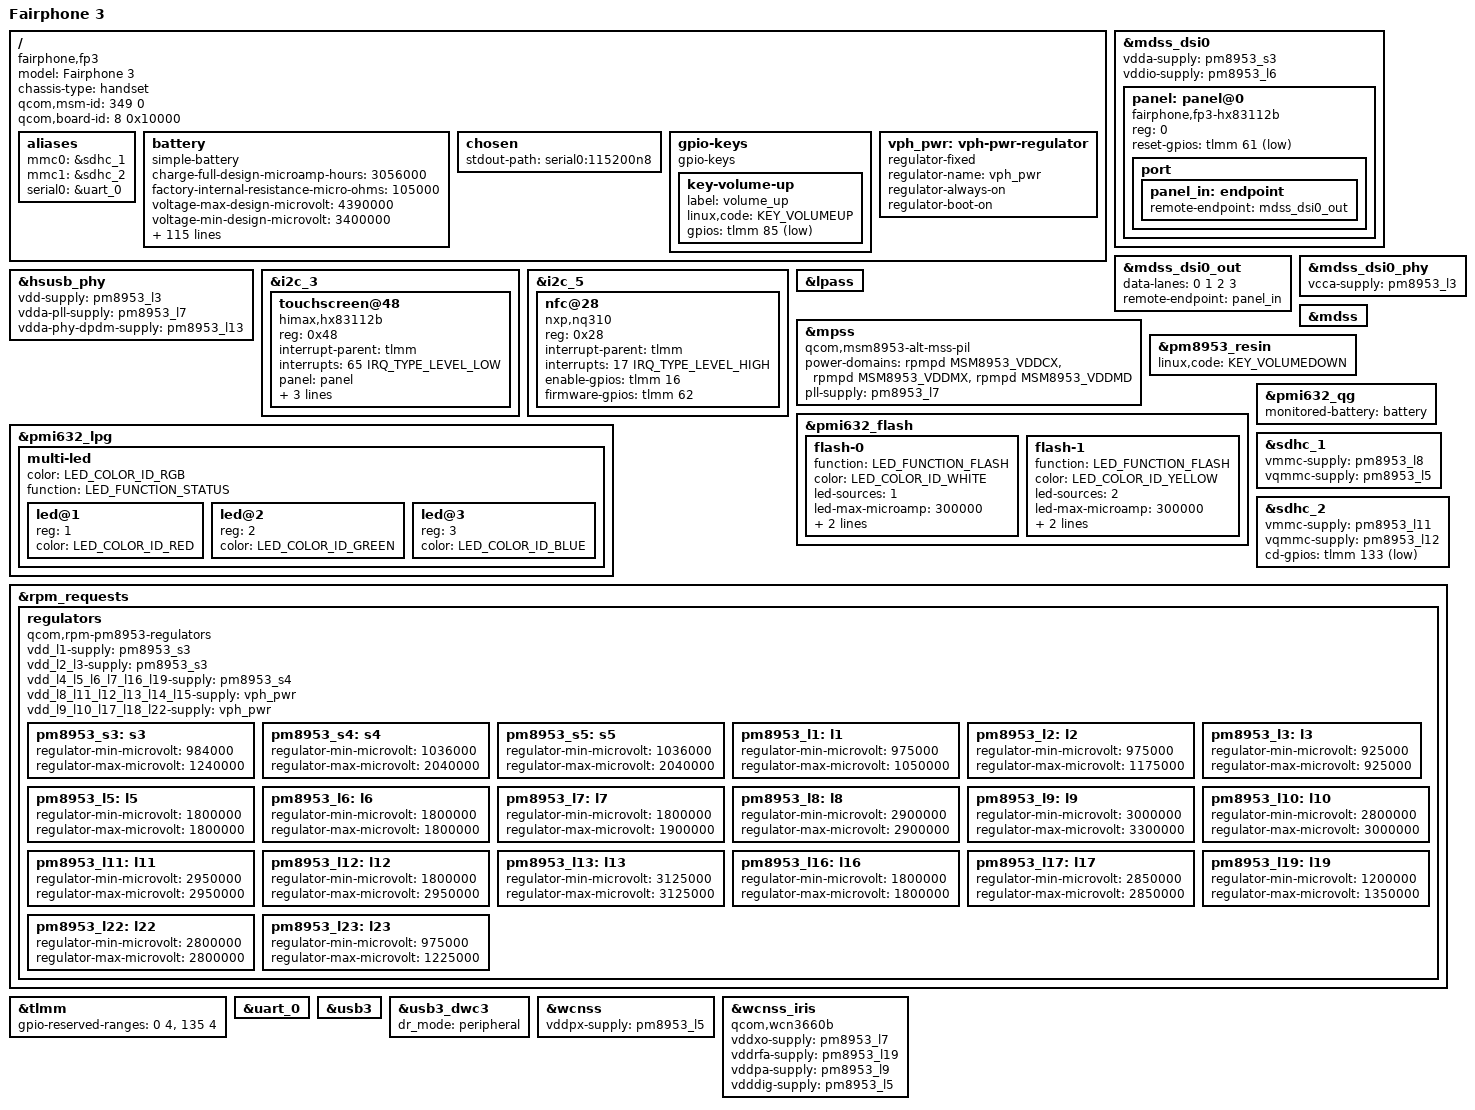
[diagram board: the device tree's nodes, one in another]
// SPDX-License-Identifier: BSD-3-Clause
/*
 * Copyright (c) 2022, Luca Weiss <luca@z3ntu.xyz>
 */
/dts-v1/;

#include <dt-bindings/leds/common.h>
#include "sdm632.dtsi"
#include "pm8953.dtsi"
#include "pmi632.dtsi"

/ {
	model = "Fairphone 3";
	compatible = "fairphone,fp3", "qcom,sdm632";
	chassis-type = "handset";
	qcom,msm-id = <349 0>;
	qcom,board-id = <8 0x10000>;

	aliases {
		mmc0 = &sdhc_1;
		mmc1 = &sdhc_2;
		serial0 = &uart_0;
	};

	battery: battery {
		compatible = "simple-battery";

		charge-full-design-microamp-hours = <3056000>; // capacity a 25 celsius when charging
		// improved guess by using the esr measuring method from qpnp-qg.c
		// which seems to tediuos to use every time
		factory-internal-resistance-micro-ohms = <105000>;
		voltage-max-design-microvolt = <4390000>;      // from downstream devicetree
		voltage-min-design-microvolt = <3400000>;      // from DEFAULT_VBATT_CUTOFF_MV in qpnp-qg.c

		// This is the lookup table for the non-charging case.
		// To have lookup tables for the charging case, too, we could
		// add them here with higher temperatur (T + 200) and request
		// the capacity for (T + 200) if we are charging
		ocv-capacity-celsius = <(-10) 0 10 25 40 50>; // 200 210 225 240 250>;
		ocv-capacity-table-0 = <4391500 100>, <4353500 98>, <4319200 96>, <4289300 94>, <4263100 92>,
				       <4238100 90>, <4213700 88>, <4189800 86>, <4163800 84>, <4136000 82>,
				       <4114900 80>, <4102900 78>, <4090800 76>, <4065400 74>, <4024600 72>,
				       <3990900 70>, <3966300 68>, <3945700 66>, <3928700 64>, <3914100 62>,
				       <3898800 60>, <3882100 58>, <3866000 56>, <3851200 54>, <3837500 52>,
				       <3827000 50>, <3818800 48>, <3811800 46>, <3805500 44>, <3799900 42>,
				       <3794700 40>, <3789900 38>, <3785300 36>, <3780500 34>, <3775700 32>,
				       <3770500 30>, <3765100 28>, <3759000 26>, <3751800 24>, <3743900 22>,
				       <3735900 20>, <3727400 18>, <3719500 16>, <3711700 14>, <3703500 12>,
				       <3694800 10>, <3689800 9>, <3684300 8>, <3676400 7>, <3663200 6>,
				       <3640100 5>, <3603400 4>, <3547700 3>, <3466700 2>, <3335700 1>,
				       <2958400 0>;
		ocv-capacity-table-1 = <4387000 100>, <4350300 98>, <4317100 96>, <4288000 94>, <4262400 92>,
				       <4237700 90>, <4212800 88>, <4188600 86>, <4165200 84>, <4142300 82>,
				       <4121800 80>, <4105500 78>, <4089100 76>, <4066200 74>, <4037000 72>,
				       <4009500 70>, <3984500 68>, <3961500 66>, <3942200 64>, <3924900 62>,
				       <3907700 60>, <3890000 58>, <3873400 56>, <3858800 54>, <3845600 52>,
				       <3833200 50>, <3821000 48>, <3811000 46>, <3803900 44>, <3798200 42>,
				       <3793500 40>, <3789700 38>, <3786100 36>, <3782700 34>, <3779300 32>,
				       <3775100 30>, <3770200 28>, <3764700 26>, <3758300 24>, <3750900 22>,
				       <3742100 20>, <3731600 18>, <3719700 16>, <3707100 14>, <3696100 12>,
				       <3686700 10>, <3681900 9>, <3677200 8>, <3670100 7>, <3659500 6>,
				       <3639500 5>, <3601700 4>, <3543700 3>, <3460400 2>, <3326600 1>,
				       <2957900 0>;
		ocv-capacity-table-2 = <4385000 100>, <4352600 98>, <4322600 96>, <4295500 94>, <4271100 92>,
				       <4247300 90>, <4223500 88>, <4200200 86>, <4177400 84>, <4155000 82>,
				       <4133300 80>, <4112600 78>, <4092300 76>, <4072300 74>, <4052500 72>,
				       <4031100 70>, <4006600 68>, <3982900 66>, <3964500 64>, <3948600 62>,
				       <3930800 60>, <3909700 58>, <3889800 56>, <3873800 54>, <3859900 52>,
				       <3847400 50>, <3836300 48>, <3826300 46>, <3817400 44>, <3809300 42>,
				       <3801600 40>, <3794100 38>, <3787900 36>, <3783500 34>, <3779800 32>,
				       <3775900 30>, <3772000 28>, <3767600 26>, <3762200 24>, <3755800 22>,
				       <3747700 20>, <3737100 18>, <3724900 16>, <3710800 14>, <3696600 12>,
				       <3689000 10>, <3686700 9>, <3684100 8>, <3680500 7>, <3672600 6>,
				       <3651300 5>, <3606600 4>, <3542100 3>, <3456400 2>, <3327000 1>,
				       <2954300 0>;
		ocv-capacity-table-3 = <4382000 100>, <4351500 98>, <4323100 96>, <4296900 94>, <4272800 92>,
				       <4249100 90>, <4225600 88>, <4202300 86>, <4179500 84>, <4156900 82>,
				       <4134700 80>, <4112700 78>, <4091500 76>, <4072000 74>, <4053600 72>,
				       <4033700 70>, <4010700 68>, <3989500 66>, <3974200 64>, <3961400 62>,
				       <3944400 60>, <3920500 58>, <3897600 56>, <3879700 54>, <3864200 52>,
				       <3851300 50>, <3840500 48>, <3830800 46>, <3821700 44>, <3813400 42>,
				       <3806100 40>, <3799300 38>, <3793000 36>, <3786900 34>, <3781200 32>,
				       <3775500 30>, <3769800 28>, <3763600 26>, <3756500 24>, <3748800 22>,
				       <3741000 20>, <3732500 18>, <3721500 16>, <3707900 14>, <3693000 12>,
				       <3688100 10>, <3686700 9>, <3685300 8>, <3682300 7>, <3676300 6>,
				       <3655100 5>, <3610100 4>, <3550400 3>, <3470700 2>, <3353300 1>,
				       <2954000 0>;
		ocv-capacity-table-4 = <4377000 100>, <4348300 98>, <4321200 96>, <4295700 94>, <4271900 92>,
				       <4248400 90>, <4225000 88>, <4201800 86>, <4178900 84>, <4156300 82>,
				       <4134000 80>, <4112300 78>, <4091000 76>, <4070700 74>, <4050800 72>,
				       <4031600 70>, <4012500 68>, <3994300 66>, <3977800 64>, <3962200 62>,
				       <3944000 60>, <3921700 58>, <3900200 56>, <3882000 54>, <3865800 52>,
				       <3852600 50>, <3841800 48>, <3832100 46>, <3823200 44>, <3814900 42>,
				       <3807500 40>, <3800500 38>, <3794000 36>, <3788400 34>, <3782600 32>,
				       <3774900 30>, <3765200 28>, <3755900 26>, <3747400 24>, <3739200 22>,
				       <3731600 20>, <3723700 18>, <3712900 16>, <3699200 14>, <3685200 12>,
				       <3681600 10>, <3680800 9>, <3679300 8>, <3676500 7>, <3669600 6>,
				       <3643500 5>, <3597000 4>, <3535600 3>, <3452400 2>, <3329900 1>,
				       <2955200 0>;
		ocv-capacity-table-5 = <4375000 100>, <4347100 98>, <4320500 96>, <4295400 94>, <4271700 92>,
				       <4248300 90>, <4225000 88>, <4201800 86>, <4178900 84>, <4156400 82>,
				       <4134100 80>, <4112300 78>, <4090900 76>, <4070500 74>, <4050600 72>,
				       <4031500 70>, <4012800 68>, <3994900 66>, <3978300 64>, <3962300 62>,
				       <3943900 60>, <3921900 58>, <3900700 56>, <3882600 54>, <3866500 52>,
				       <3853200 50>, <3842300 48>, <3832500 46>, <3823400 44>, <3815000 42>,
				       <3807400 40>, <3800200 38>, <3793600 36>, <3788000 34>, <3782100 32>,
				       <3773300 30>, <3761000 28>, <3750000 26>, <3741100 24>, <3732800 22>,
				       <3725000 20>, <3717000 18>, <3706200 16>, <3692600 14>, <3679300 12>,
				       <3676300 10>, <3675200 9>, <3673600 8>, <3671000 7>, <3662500 6>,
				       <3633500 5>, <3586000 4>, <3524200 3>, <3439600 2>, <3314800 1>,
				       <2955300 0>;
	};

	chosen {
		stdout-path = "serial0:115200n8";
	};

	gpio-keys {
		compatible = "gpio-keys";

		key-volume-up {
			label = "volume_up";
			linux,code = <KEY_VOLUMEUP>;
			gpios = <&tlmm 85 GPIO_ACTIVE_LOW>;
		};
	};

	vph_pwr: vph-pwr-regulator {
		compatible = "regulator-fixed";
		regulator-name = "vph_pwr";
		regulator-always-on;
		regulator-boot-on;
	};
};

&mdss_dsi0 {
	vdda-supply = <&pm8953_s3>;
	vddio-supply = <&pm8953_l6>;

	status = "okay";

	panel: panel@0 {
		compatible = "fairphone,fp3-hx83112b";
		reg = <0>;

		reset-gpios = <&tlmm 61 GPIO_ACTIVE_LOW>;

		// Downstream:
		// lab-supply = <&lcdb_ldo_vreg>;
		// ibb-supply = <&lcdb_ncp_vreg>;

		// lcdb driver is not yet in mainline
		// vsp-supply = <>;
		// vsn-supply = <>;

		port {
			panel_in: endpoint {
				remote-endpoint = <&mdss_dsi0_out>;
			};
		};
	};
};

&mdss_dsi0_out {
	data-lanes = <0 1 2 3>;
	remote-endpoint = <&panel_in>;
};

&mdss_dsi0_phy {
	vcca-supply = <&pm8953_l3>;

	status = "okay";
};

&hsusb_phy {
	status = "okay";
	vdd-supply = <&pm8953_l3>;
	vdda-pll-supply = <&pm8953_l7>;
	vdda-phy-dpdm-supply = <&pm8953_l13>;
};

&i2c_3 {
	status = "okay";

	touchscreen@48 {
		compatible = "himax,hx83112b";
		reg = <0x48>;
		interrupt-parent = <&tlmm>;
		interrupts = <65 IRQ_TYPE_LEVEL_LOW>;
		panel = <&panel>;
		touchscreen-size-x = <1080>;
		touchscreen-size-y = <2160>;
		reset-gpios = <&tlmm 64 GPIO_ACTIVE_LOW>;
	};
};

&i2c_5 {
	status = "okay";

	nfc@28 {
		compatible = "nxp,nq310", "nxp,nxp-nci-i2c";
		reg = <0x28>;

		interrupt-parent = <&tlmm>;
		interrupts = <17 IRQ_TYPE_LEVEL_HIGH>;

		enable-gpios = <&tlmm 16 GPIO_ACTIVE_HIGH>;
		firmware-gpios = <&tlmm 62 GPIO_ACTIVE_HIGH>;
	};
};

&lpass {
	status = "okay";
};

&mpss {
	status = "okay";
	compatible = "qcom,msm8953-alt-mss-pil";

	power-domains = <&rpmpd MSM8953_VDDCX>, <&rpmpd MSM8953_VDDMX>, <&rpmpd MSM8953_VDDMD>;
	power-domain-names = "cx", "mx", "mss";

	pll-supply = <&pm8953_l7>;
};

&mdss {
	status = "okay";
};

&pm8953_resin {
	status = "okay";
	linux,code = <KEY_VOLUMEDOWN>;
};

&pmi632_flash {
	status = "okay";

	flash-0 {
		function = LED_FUNCTION_FLASH;
		color = <LED_COLOR_ID_WHITE>;
		led-sources = <1>;
		led-max-microamp = <300000>;
		flash-max-microamp = <1000000>;
		flash-max-timeout-us = <1280000>;
	};

	flash-1 {
		function = LED_FUNCTION_FLASH;
		color = <LED_COLOR_ID_YELLOW>;
		led-sources = <2>;
		led-max-microamp = <300000>;
		flash-max-microamp = <1000000>;
		flash-max-timeout-us = <1280000>;
	};
};

&pmi632_lpg {
	status = "okay";

	multi-led {
		color = <LED_COLOR_ID_RGB>;
		function = LED_FUNCTION_STATUS;

		#address-cells = <1>;
		#size-cells = <0>;

		led@1 {
			reg = <1>;
			color = <LED_COLOR_ID_RED>;
		};

		led@2 {
			reg = <2>;
			color = <LED_COLOR_ID_GREEN>;
		};

		led@3 {
			reg = <3>;
			color = <LED_COLOR_ID_BLUE>;
		};
	};
};

&pmi632_qg {
	status = "okay";
	monitored-battery = <&battery>;
};

&sdhc_1 {
	status = "okay";
	vmmc-supply = <&pm8953_l8>;
	vqmmc-supply = <&pm8953_l5>;
};

&sdhc_2 {
	status = "okay";
	vmmc-supply = <&pm8953_l11>;
	vqmmc-supply = <&pm8953_l12>;

	cd-gpios = <&tlmm 133 GPIO_ACTIVE_LOW>;
};

&rpm_requests {
	regulators {
		compatible = "qcom,rpm-pm8953-regulators";

		vdd_l1-supply = <&pm8953_s3>;
		vdd_l2_l3-supply = <&pm8953_s3>;
		vdd_l4_l5_l6_l7_l16_l19-supply = <&pm8953_s4>;
		vdd_l8_l11_l12_l13_l14_l15-supply = <&vph_pwr>;
		vdd_l9_l10_l17_l18_l22-supply = <&vph_pwr>;

		pm8953_s3: s3 {
			regulator-min-microvolt = <984000>;
			regulator-max-microvolt = <1240000>;
		};
		pm8953_s4: s4 {
			regulator-min-microvolt = <1036000>;
			regulator-max-microvolt = <2040000>;
		};
		pm8953_s5: s5 {
			regulator-min-microvolt = <1036000>;
			regulator-max-microvolt = <2040000>;
		};

		pm8953_l1: l1 {
			regulator-min-microvolt = <975000>;
			regulator-max-microvolt = <1050000>;
		};
		pm8953_l2: l2 {
			regulator-min-microvolt = <975000>;
			regulator-max-microvolt = <1175000>;
		};
		pm8953_l3: l3 {
			regulator-min-microvolt = <925000>;
			regulator-max-microvolt = <925000>;
		};
		pm8953_l5: l5 {
			regulator-min-microvolt = <1800000>;
			regulator-max-microvolt = <1800000>;
		};
		pm8953_l6: l6 {
			regulator-min-microvolt = <1800000>;
			regulator-max-microvolt = <1800000>;
		};
		pm8953_l7: l7 {
			regulator-min-microvolt = <1800000>;
			regulator-max-microvolt = <1900000>;
		};
		pm8953_l8: l8 {
			regulator-min-microvolt = <2900000>;
			regulator-max-microvolt = <2900000>;
		};
		pm8953_l9: l9 {
			regulator-min-microvolt = <3000000>;
			regulator-max-microvolt = <3300000>;
		};
		pm8953_l10: l10 {
			regulator-min-microvolt = <2800000>;
			regulator-max-microvolt = <3000000>;
		};
		pm8953_l11: l11 {
			regulator-min-microvolt = <2950000>;
			regulator-max-microvolt = <2950000>;
		};
		pm8953_l12: l12 {
			regulator-min-microvolt = <1800000>;
			regulator-max-microvolt = <2950000>;
		};
		pm8953_l13: l13 {
			regulator-min-microvolt = <3125000>;
			regulator-max-microvolt = <3125000>;
		};
		pm8953_l16: l16 {
			regulator-min-microvolt = <1800000>;
			regulator-max-microvolt = <1800000>;
		};
		pm8953_l17: l17 {
			regulator-min-microvolt = <2850000>;
			regulator-max-microvolt = <2850000>;
		};
		pm8953_l19: l19 {
			regulator-min-microvolt = <1200000>;
			regulator-max-microvolt = <1350000>;
		};
		pm8953_l22: l22 {
			regulator-min-microvolt = <2800000>;
			regulator-max-microvolt = <2800000>;
		};
		pm8953_l23: l23 {
			regulator-min-microvolt = <975000>;
			regulator-max-microvolt = <1225000>;
		};
	};
};

&tlmm {
	/*
	 * 0-3: unused but protected by TZ
	 * 135-138: fingerprint reader (SPI)
	 */
	gpio-reserved-ranges = <0 4>, <135 4>;
};

&uart_0 {
	status = "okay";
};

&usb3 {
	status = "okay";
};

&usb3_dwc3 {
	dr_mode = "peripheral";
};

&wcnss {
	status = "okay";

	vddpx-supply = <&pm8953_l5>;
};

&wcnss_iris {
	compatible = "qcom,wcn3660b";

	vddxo-supply = <&pm8953_l7>;
	vddrfa-supply = <&pm8953_l19>;
	vddpa-supply = <&pm8953_l9>;
	vdddig-supply = <&pm8953_l5>;
};

